# YT9218 register map
Vendor: Motorcomm; Series: YT921x; File version: 1.0
Registers are 32-bit, read-write, no defined reset value unless marked. A register's access mark holds for its fields unless they carry their own. Offsets are from the block's base; [hi:lo] are bit positions; lines under a group give offsets from that group; {n}, {i} and the like mark numbered series.

## LED — LED control
Base 0x000D0000
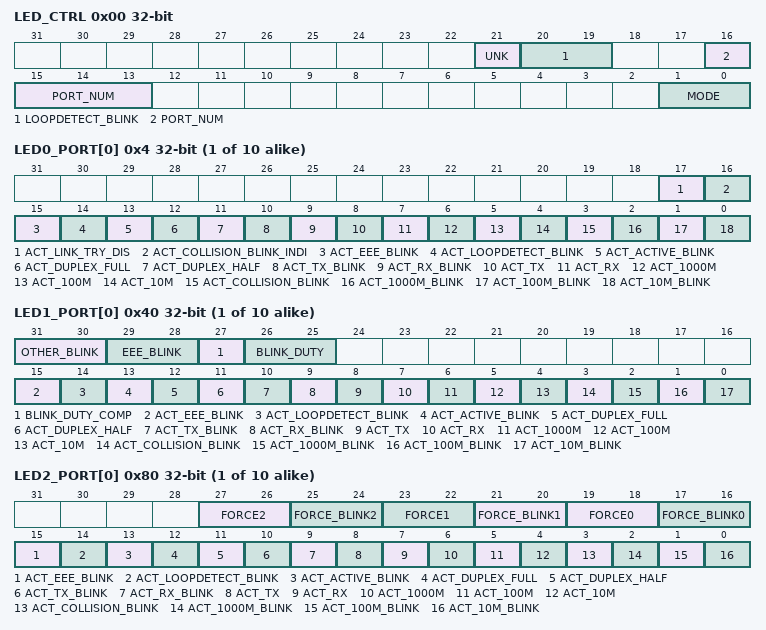
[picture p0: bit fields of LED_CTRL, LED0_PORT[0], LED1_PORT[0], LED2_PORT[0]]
0x00 LED_CTRL — Chooses between parallel and serial LED outputs and sets the loop detection blink rate.
  [21] UNK — The vendor SDK function fal_tiger_led_enable() sets the bit under the comment "enabel LED". The Linux driver does not name its function.
  [20:19] LOOPDETECT_BLINK — Blink cycle that signals a detected loop. The comment on the field gives the cycle as 512 ms times the field value. The vendor SDK list yt_led_loopdetect_blink_rate_t gives 512 ms for the value 0 and 2048 ms for the value 3, which is 512 ms times the field value plus one. It is not known which is right.
  [16:13] PORT_NUM — Number of ports shifted out in serial mode.
  [1:0] MODE — LED output mode.
    0=PARALLEL (One pin per LED); 2=SERIAL (LED states shifted out on a clock and data pin pair)
{0x4+4i} LED0_PORT[{i}] (i=0..9) — Conditions that light or blink LED 0 of one port. It is inferred from yt921x_led_trigger_set, which sets several bits at once, that each set bit adds one condition and that the LED shows the combination. LEDs explains the three LED groups. Index: port = 0 to 9.
  [17] ACT_LINK_TRY_DIS — Only LED 0 has the field. The vendor SDK action list names the bit LED_ACTION_DISABLE_LINK_TRY, and fal_tiger_led_action_set() sets it for LED 0 in every case, under the comment "tiger must set disable_link_try bit to 1". The Linux driver disagrees: yt921x_led_trigger_set writes LED 0 with a mask that holds this bit and never sets it, so it clears the bit. What the bit does is not known.
  [16] ACT_COLLISION_BLINK_INDI — Only LED 0 has the field. The vendor SDK action list names the bit LED_ACTION_COLLISION_BLINK. It is inferred from the name that the LED blinks on a collision.
  [15] ACT_EEE_BLINK — Blink while the port is in low power idle.
  [14] ACT_LOOPDETECT_BLINK — Blink when a loop is detected on the port.
  [13] ACT_ACTIVE_BLINK — Blink on any activity.
  [12] ACT_DUPLEX_FULL — On while the link is up in full duplex.
  [11] ACT_DUPLEX_HALF — On while the link is up in half duplex.
  [10] ACT_TX_BLINK — Blink while frames are sent.
  [9] ACT_RX_BLINK — Blink while frames are received.
  [8] ACT_TX — On while frames are sent.
  [7] ACT_RX — On while frames are received.
  [6] ACT_1000M — On while the link is up at 1000 Mbit/s.
  [5] ACT_100M — On while the link is up at 100 Mbit/s.
  [4] ACT_10M — On while the link is up at 10 Mbit/s.
  [3] ACT_COLLISION_BLINK — Blink on collisions.
  [2] ACT_1000M_BLINK — Blink on activity at 1000 Mbit/s.
  [1] ACT_100M_BLINK — Blink on activity at 100 Mbit/s.
  [0] ACT_10M_BLINK — Blink on activity at 10 Mbit/s.
{0x40+4i} LED1_PORT[{i}] (i=0..9) — Conditions that light or blink LED 1 of one port, plus the blink timing shared by all three LEDs of the port. Index: port = 0 to 9.
  [31:30] OTHER_BLINK — Alternative blink cycle. The cycle is 512 ms shifted right by the field value. An LED uses it when its LED2_PORT.FORCE_BLINK field is 3.
  [29:28] EEE_BLINK — Blink cycle of the low power idle indication. The cycle is 512 ms shifted right by the field value.
  [27] BLINK_DUTY_COMP — Swaps the on and off parts of the blink cycle. LED1_PORT.BLINK_DUTY then gives the off fraction.
  [26:25] BLINK_DUTY — Fraction of the blink cycle the LED is on.
    0=V1_2 (On for 1/2 of the cycle); 1=V2_3 (On for 2/3 of the cycle); 2=V3_4 (On for 3/4 of the cycle); 3=V5_6 (On for 5/6 of the cycle)
  [15] ACT_EEE_BLINK — Blink while the port is in low power idle.
  [14] ACT_LOOPDETECT_BLINK — Blink when a loop is detected on the port.
  [13] ACT_ACTIVE_BLINK — Blink on any activity.
  [12] ACT_DUPLEX_FULL — On while the link is up in full duplex.
  [11] ACT_DUPLEX_HALF — On while the link is up in half duplex.
  [10] ACT_TX_BLINK — Blink while frames are sent.
  [9] ACT_RX_BLINK — Blink while frames are received.
  [8] ACT_TX — On while frames are sent.
  [7] ACT_RX — On while frames are received.
  [6] ACT_1000M — On while the link is up at 1000 Mbit/s.
  [5] ACT_100M — On while the link is up at 100 Mbit/s.
  [4] ACT_10M — On while the link is up at 10 Mbit/s.
  [3] ACT_COLLISION_BLINK — Blink on collisions.
  [2] ACT_1000M_BLINK — Blink on activity at 1000 Mbit/s.
  [1] ACT_100M_BLINK — Blink on activity at 100 Mbit/s.
  [0] ACT_10M_BLINK — Blink on activity at 10 Mbit/s.
{0x80+4i} LED2_PORT[{i}] (i=0..9) — Conditions that light or blink LED 2 of one port, plus the forced state of all three LEDs of the port. Index: port = 0 to 9.
  [4n+19:4n+18] FORCE{n} (n=0..2) — Forced state of LED group grp of this port.
    0=DONTCARE (Not forced. The LED follows its behaviour bits); 1=BLINK (Blink at the rate in LED2_PORT.FORCE_BLINK); 2=ON; 3=OFF
  [4n+17:4n+16] FORCE_BLINK{n} (n=0..2) — Blink cycle of an LED that is forced to blink. The cycle is 512 ms shifted left by the field value.
    3=OTHER (Use the cycle in LED1_PORT.OTHER_BLINK)
  [15] ACT_EEE_BLINK — Blink while the port is in low power idle.
  [14] ACT_LOOPDETECT_BLINK — Blink when a loop is detected on the port.
  [13] ACT_ACTIVE_BLINK — Blink on any activity.
  [12] ACT_DUPLEX_FULL — On while the link is up in full duplex.
  [11] ACT_DUPLEX_HALF — On while the link is up in half duplex.
  [10] ACT_TX_BLINK — Blink while frames are sent.
  [9] ACT_RX_BLINK — Blink while frames are received.
  [8] ACT_TX — On while frames are sent.
  [7] ACT_RX — On while frames are received.
  [6] ACT_1000M — On while the link is up at 1000 Mbit/s.
  [5] ACT_100M — On while the link is up at 100 Mbit/s.
  [4] ACT_10M — On while the link is up at 10 Mbit/s.
  [3] ACT_COLLISION_BLINK — Blink on collisions.
  [2] ACT_1000M_BLINK — Blink on activity at 1000 Mbit/s.
  [1] ACT_100M_BLINK — Blink on activity at 100 Mbit/s.
  [0] ACT_10M_BLINK — Blink on activity at 10 Mbit/s.
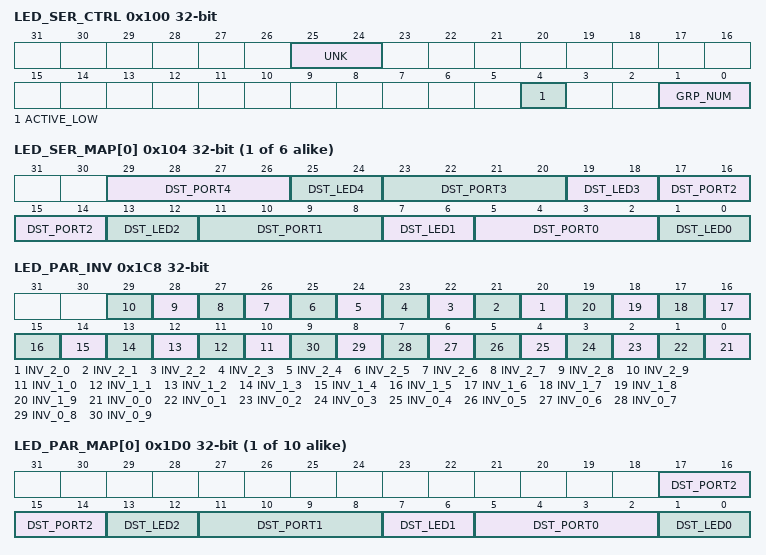
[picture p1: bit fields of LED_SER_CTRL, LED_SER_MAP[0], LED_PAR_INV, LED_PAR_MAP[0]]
0x100 LED_SER_CTRL — Settings of the serial LED output.
  [25:24] UNK — The vendor SDK function fal_tiger_led_serial_enable_set() sets both bits to turn the serial LED output on and clears both to turn it off. The comment on the field in the Linux driver reads "delay?".
  [4] ACTIVE_LOW — Serial LED data is active low.
  [1:0] GRP_NUM — Number of LED groups shifted out per port minus one.
{0x104+4i} LED_SER_MAP[{i}] (i=0..5) — Chooses which LED is shifted out at each position of the serial stream. One register holds five positions; index half is 0 for ports 0 to 4 and 1 for ports 5 to 9. Index: grp = 0 to 2, half = 0 to 1. Flat index = 2 × (2 − grp) + half.
  [6n+5:6n+2] DST_PORT{n} (n=0..4) — Port whose LED is shown at position slot.
  [6n+1:6n] DST_LED{n} (n=0..4) — LED group shown at position slot.
0x1C4 LED_PAR_PORTS — Parallel LED outputs in use. The Linux driver defines the address only.
  [31:0] VALUE — The vendor SDK function fal_tiger_led_parallel_output_set() writes a port mask to bits 9 to 0, one bit per port, under the comment "select output port mask of parallel LED". Bits 31 to 10 are not known.
0x1C8 LED_PAR_INV — Inverts individual parallel LED outputs. With the bit clear the pin is low while the LED is on, which suits an LED wired active low; set the bit for an LED wired active high.
  [n+20] INV_2_{n} (n=0..9) — Inverts the output of one LED group of one port. The bit number is 10 × grp + port.
  [n+10] INV_1_{n} (n=0..9) — Inverts the output of one LED group of one port. The bit number is 10 × grp + port.
  [n] INV_0_{n} (n=0..9) — Inverts the output of one LED group of one port. The bit number is 10 × grp + port.
{0x1D0+4i} LED_PAR_MAP[{i}] (i=0..9) — Chooses which LED each parallel LED pin of one port position shows. Index: port = 0 to 9.
  [6n+5:6n+2] DST_PORT{n} (n=0..2) — Port whose LED is shown on pin group grp.
  [6n+1:6n] DST_LED{n} (n=0..2) — LED group shown on pin group grp.
